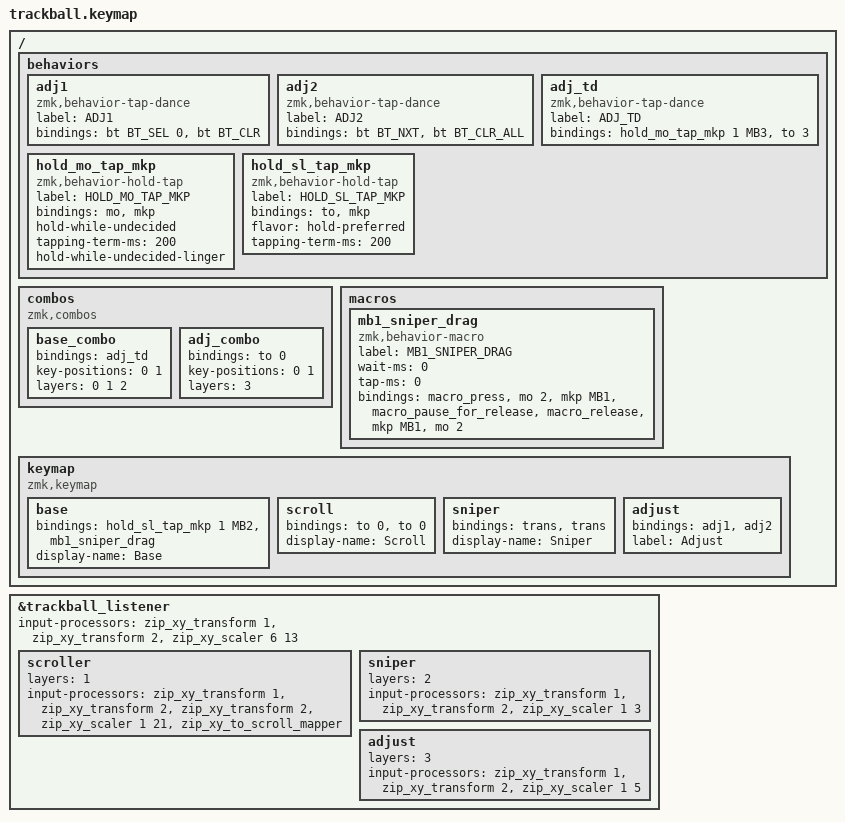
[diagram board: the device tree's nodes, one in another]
#include "keys_ru.h"
#include <dt-bindings/zmk/input_transform.h>
#include <input/processors.dtsi>
#include <zephyr/dt-bindings/input/input-event-codes.h>
#include <behaviors.dtsi>
#include <dt-bindings/zmk/bt.h>
#include <dt-bindings/zmk/pointing.h>

/ {
    behaviors {
        adj1: adj1 {
            compatible = "zmk,behavior-tap-dance";
            label = "ADJ1";
            #binding-cells = <0>;
            bindings = <&bt BT_SEL 0>, <&bt BT_CLR>;
        };

        adj2: adj2 {
            compatible = "zmk,behavior-tap-dance";
            label = "ADJ2";
            #binding-cells = <0>;
            bindings = <&bt BT_NXT>, <&bt BT_CLR_ALL>;
        };

        adj_td: adj_td {
            compatible = "zmk,behavior-tap-dance";
            label = "ADJ_TD";
            #binding-cells = <0>;
            bindings = <&hold_mo_tap_mkp 1 MB3>, <&to 3>;
        };

        hold_mo_tap_mkp: hold_mo_tap_mkp {
            compatible = "zmk,behavior-hold-tap";
            label = "HOLD_MO_TAP_MKP";
            bindings = <&mo>, <&mkp>;

            #binding-cells = <2>;
            hold-while-undecided;
            tapping-term-ms = <200>;
            hold-while-undecided-linger;
        };

        hold_sl_tap_mkp: hold_sl_tap_mkp {
            compatible = "zmk,behavior-hold-tap";
            label = "HOLD_SL_TAP_MKP";
            bindings = <&to>, <&mkp>;

            #binding-cells = <2>;
            flavor = "hold-preferred";
            tapping-term-ms = <200>;
        };
    };

    combos {
        compatible = "zmk,combos";

        base_combo {
            bindings = <&adj_td>;
            key-positions = <0 1>;
            layers = <0 1 2>;
        };

        adj_combo {
            bindings = <&to 0>;
            key-positions = <0 1>;
            layers = <3>;
        };
    };

    macros {
        mb1_sniper_drag: mb1_sniper_drag {
            compatible = "zmk,behavior-macro";
            label = "MB1_SNIPER_DRAG";
            #binding-cells = <0>;

            wait-ms = <0>;
            tap-ms = <0>;

            bindings =
                <&macro_press &mo 2 &mkp MB1>,
                <&macro_pause_for_release>,
                <&macro_release &mkp MB1 &mo 2>;
        };
    };

    keymap {
        compatible = "zmk,keymap";

        base {
            bindings = <
&hold_sl_tap_mkp 1 MB2  &mb1_sniper_drag
            >;

            display-name = "Base";
        };

        scroll {
            bindings = <
&to 0  &to 0
            >;

            display-name = "Scroll";
        };

        sniper {
            bindings = <
&trans  &trans
            >;

            display-name = "Sniper";
        };

        adjust {
            bindings = <
&adj1  &adj2
            >;

            label = "Adjust";
        };
    };
};

&trackball_listener {
    input-processors = 
        <&zip_xy_transform 1>,      // 1. Поворот 90° CW
        <&zip_xy_transform 2>,      // 2. Инвертировать Y (это бывший X)
        <&zip_xy_scaler 6 13>;

    scroller {
        layers = <1>;
        input-processors =
            <&zip_xy_transform 1>,  // поворот
            <&zip_xy_transform 2>,  // инвертировать Y (для горизонтали)
            <&zip_xy_transform 2>,  // еще раз инвертировать Y (для скролла)
            <&zip_xy_scaler 1 21>,
            <&zip_xy_to_scroll_mapper>;
    };

    sniper {
        layers = <2>;
        input-processors = 
            <&zip_xy_transform 1>,
            <&zip_xy_transform 2>,  // инвертировать Y
            <&zip_xy_scaler 1 3>;
    };

    adjust {
        layers = <3>;
        input-processors = 
            <&zip_xy_transform 1>,
            <&zip_xy_transform 2>,  // инвертировать Y
            <&zip_xy_scaler 1 5>;
    };
};
